# PIC32CM1216LS00048 register map
Vendor: Microchip Technology; Series: PIC32CMLS00; File version: 0
CPU: CM23 r0p0, little endian, MPU, no FPU, 2 interrupt priority bits, 71 interrupts
Registers are 32-bit, read-write, reset 0x0 unless marked. A register's access mark holds for its fields unless they carry their own. Offsets are from the block's base; [hi:lo] are bit positions; lines under a group give offsets from that group; {n}, {i} and the like mark numbered series; 'fields as' and 'values as' point back to an identical list.

## EIC — External Interrupt Controller
Base 0x40002800
Same registers: EIC_SEC 0x40002A00
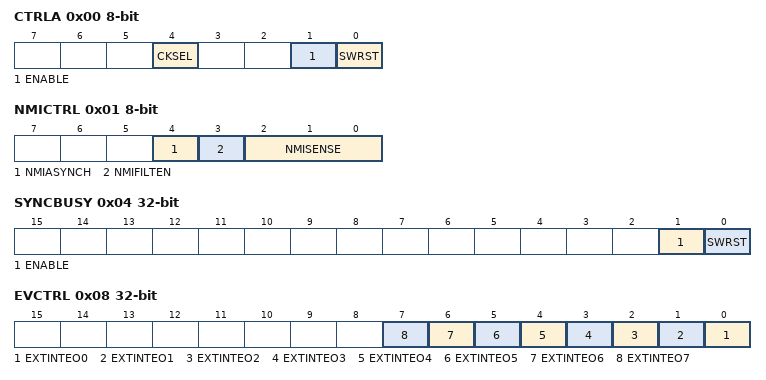
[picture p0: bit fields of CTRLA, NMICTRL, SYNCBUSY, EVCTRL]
0x00 CTRLA 8-bit — Control A
  [4] CKSEL — Clock Selection
    0=CLK_GCLK (Clocked by GCLK); 1=CLK_ULP32K (Clocked by ULP32K)
  [1] ENABLE
  [0] SWRST — Software Reset
0x01 NMICTRL 8-bit — Non-Maskable Interrupt Control
  [4] NMIASYNCH — Asynchronous Edge Detection Mode
    0=SYNC (Edge detection is clock synchronously operated); 1=ASYNC (Edge detection is clock asynchronously operated)
  [3] NMIFILTEN — Non-Maskable Interrupt Filter Enable
  [2:0] NMISENSE — Non-Maskable Interrupt Sense Configuration
    0=NONE (No detection); 1=RISE (Rising-edge detection); 2=FALL (Falling-edge detection); 3=BOTH (Both-edges detection); 4=HIGH (High-level detection); 5=LOW (Low-level detection)
0x02 NMIFLAG 8-bit write-1-clears — Non-Maskable Interrupt Flag Status and Clear
  [0] NMI — Non-Maskable Interrupt
0x04 SYNCBUSY ro — Synchronization Busy
  [1] ENABLE — Enable Synchronization Busy Status
  [0] SWRST — Software Reset Synchronization Busy Status
0x08 EVCTRL — Event Control
  [n] EXTINTEO{n} (n=0..7) — External Interrupt {n} Event Output Enable
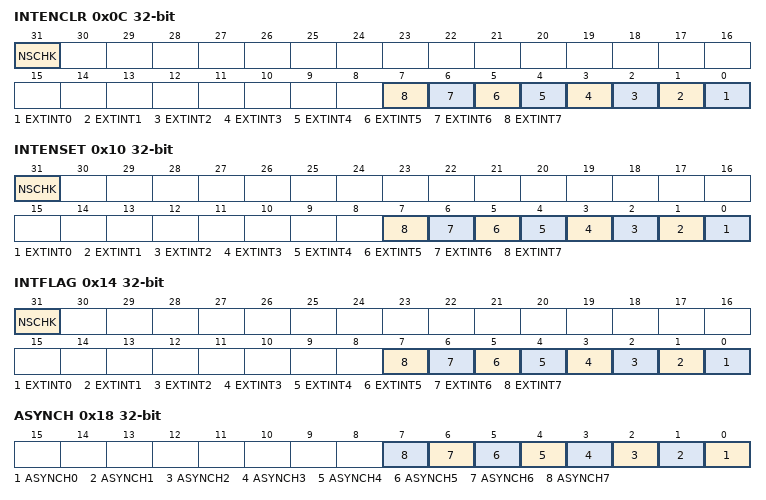
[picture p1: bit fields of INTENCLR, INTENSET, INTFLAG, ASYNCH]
0x0C INTENCLR write-1-clears — Interrupt Enable Clear
  [31] NSCHK — Non-secure Check Interrupt Enable
  [n] EXTINT{n} (n=0..7) — External Interrupt {n} Enable
0x10 INTENSET write-1-sets — Interrupt Enable Set
  fields as INTENCLR
0x14 INTFLAG write-1-clears — Interrupt Flag Status and Clear
  [31] NSCHK — Non-secure Check Interrupt
  [n] EXTINT{n} (n=0..7) — External Interrupt {n}
0x18 ASYNCH — External Interrupt Asynchronous Mode
  [all] fields
    values as NMICTRL.NMIASYNCH
  [n] ASYNCH{n} (n=0..7) — Asynchronous Edge Detection Mode of EXTINT{n}
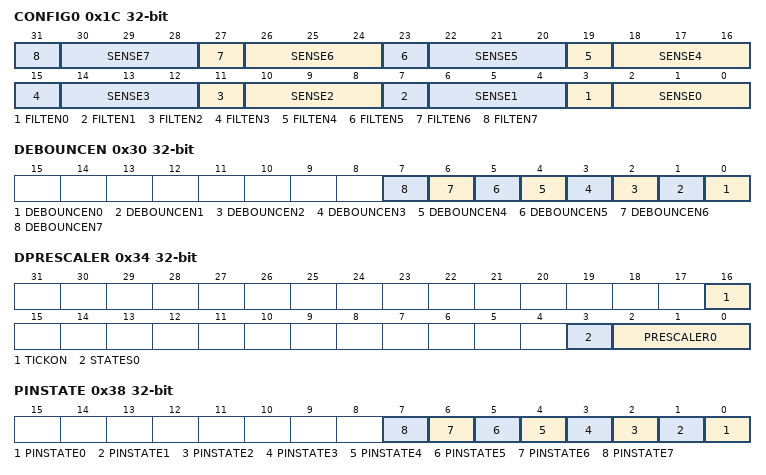
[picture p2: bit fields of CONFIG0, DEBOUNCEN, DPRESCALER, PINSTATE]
0x1C CONFIG0 — External Interrupt Sense Configuration
  [4n+3] FILTEN{n} (n=0..7) — Filter Enable {n}
  [4n+2:4n] SENSE{n} (n=0..7) — Input Sense Configuration {n}
    0=NONE (No detection); 1=RISE (Rising edge detection); 2=FALL (Falling edge detection); 3=BOTH (Both edges detection); 4=HIGH (High level detection); 5=LOW (Low level detection)
0x30 DEBOUNCEN — Debouncer Enable
  [n] DEBOUNCEN{n} (n=0..7) — Debouncer Enable of EXTINT{n}
0x34 DPRESCALER — Debouncer Prescaler
  [16] TICKON — Pin Sampler frequency selection
    0=CLK_GCLK_EIC (Clocked by GCLK); 1=CLK_LFREQ (Clocked by Low Frequency Clock)
  [3] STATES0 — Debouncer number of states
    0=LFREQ3 (3 low frequency samples); 1=LFREQ7 (7 low frequency samples)
  [2:0] PRESCALER0 — Debouncer Prescaler
    0=DIV2 (EIC clock divided by 2); 1=DIV4 (EIC clock divided by 4); 2=DIV8 (EIC clock divided by 8); 3=DIV16 (EIC clock divided by 16); 4=DIV32 (EIC clock divided by 32); 5=DIV64 (EIC clock divided by 64); 6=DIV128 (EIC clock divided by 128); 7=DIV256 (EIC clock divided by 256)
0x38 PINSTATE ro
  [n] PINSTATE{n} (n=0..7) — Pin State of EXTINT{n}
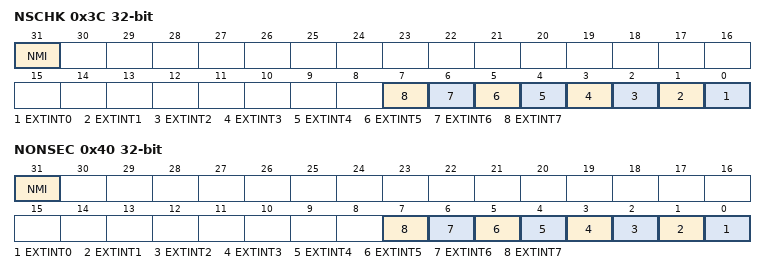
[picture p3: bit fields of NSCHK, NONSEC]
0x3C NSCHK — Non-secure Interrupt Check Enable
  [31] NMI — Non-Maskable External Interrupt Nonsecure Check Enable
  [n] EXTINT{n} (n=0..7) — External Interrupt {n} Nonsecure Check Enable
0x40 NONSEC — Non-secure Interrupt
  [31] NMI — Non-Maskable Interrupt Nonsecure Enable
  [n] EXTINT{n} (n=0..7) — External Interrupt {n} Nonsecure Enable

## EVSYS — Event System Interface
Base 0x42000000
Same registers: EVSYS_SEC 0x42000200
0x00 CTRLA 8-bit wo — Control
  [0] SWRST — Software Reset
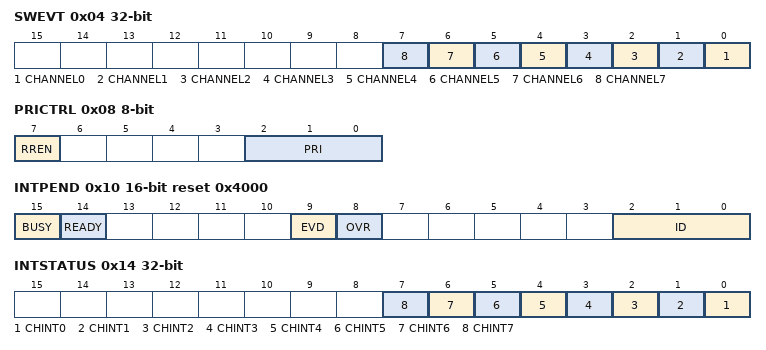
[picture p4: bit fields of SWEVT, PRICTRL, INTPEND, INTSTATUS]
0x04 SWEVT wo — Software Event
  [n] CHANNEL{n} (n=0..7) — Channel {n} Software Selection
0x08 PRICTRL 8-bit — Priority Control
  [7] RREN — Round-Robin Scheduling Enable
  [2:0] PRI — Channel Priority Number
0x10 INTPEND 16-bit reset 0x4000 — Channel Pending Interrupt
  [15] BUSY
  [14] READY
  [9] EVD — Channel Event Detected
  [8] OVR — Channel Overrun
  [2:0] ID — Channel ID
0x14 INTSTATUS ro — Interrupt Status
  [n] CHINT{n} (n=0..7) — Channel {n} Pending Interrupt
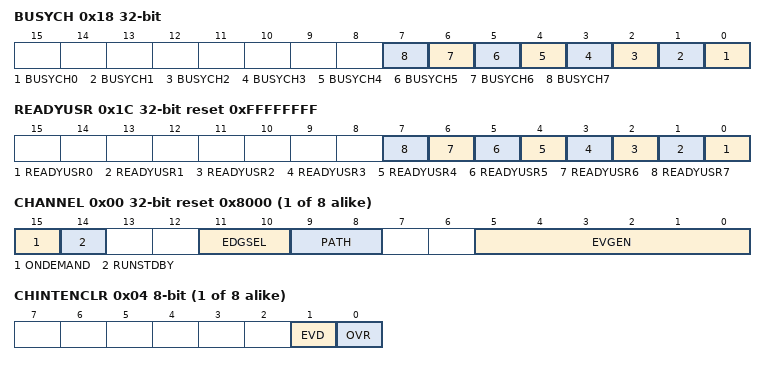
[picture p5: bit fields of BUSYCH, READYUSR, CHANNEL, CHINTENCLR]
0x18 BUSYCH ro — Busy Channels
  [n] BUSYCH{n} (n=0..7) — Busy Channel {n}
0x1C READYUSR ro reset 0xFFFFFFFF — Ready Users
  [n] READYUSR{n} (n=0..7) — Ready User for Channel {n}
{0x20+8i} CHANNEL[{i}] (i=0..7) group
  0x00 CHANNEL reset 0x8000 — Channel n Control
    [15] ONDEMAND — Generic Clock On Demand
    [14] RUNSTDBY — Run in standby
    [11:10] EDGSEL — Edge Detection Selection
      0=NO_EVT_OUTPUT (No event output when using the resynchronized or synchronous path); 1=RISING_EDGE (Event detection only on the rising edge of the signal from the event generator when using the resynchronized or synchronous path); 2=FALLING_EDGE (Event detection only on the falling edge of the signal from the event generator when using the resynchronized or synchronous path); 3=BOTH_EDGES (Event detection on rising and falling edges of the signal from the event generator when using the resynchronized or synchronous path)
    [9:8] PATH — Path Selection
      0=SYNCHRONOUS (Synchronous path); 1=RESYNCHRONIZED (Resynchronized path); 2=ASYNCHRONOUS (Asynchronous path)
    [5:0] EVGEN — Event Generator Selection
  0x04 CHINTENCLR 8-bit write-1-clears — Channel n Interrupt Enable Clear
    [1] EVD — Channel Event Detected Interrupt Disable
    [0] OVR — Channel Overrun Interrupt Disable
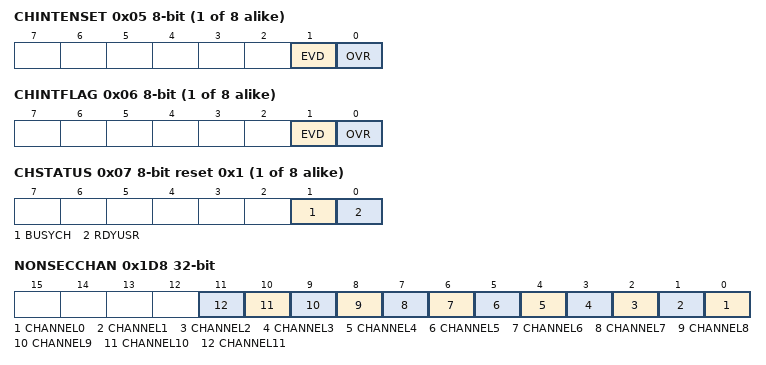
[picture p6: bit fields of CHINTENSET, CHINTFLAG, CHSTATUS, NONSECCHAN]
  0x05 CHINTENSET 8-bit write-1-sets — Channel n Interrupt Enable Set
    [1] EVD — Channel Event Detected Interrupt Enable
    [0] OVR — Channel Overrun Interrupt Enable
  0x06 CHINTFLAG 8-bit write-1-clears — Channel n Interrupt Flag Status and Clear
    [1] EVD — Channel Event Detected
    [0] OVR — Channel Overrun
  0x07 CHSTATUS 8-bit ro reset 0x1 — Channel n Status
    [1] BUSYCH — Busy Channel
    [0] RDYUSR — Ready User
{0x120+i} USER[{i}] (i=0..27) 8-bit — User Multiplexer n
  [3:0] CHANNEL — Channel Event Selection
0x1D4 INTENCLR 8-bit write-1-clears — Interrupt Enable Clear
  [0] NSCHK — Non-Secure Check Interrupt Enable
0x1D5 INTENSET 8-bit write-1-sets — Interrupt Enable Set
  [0] NSCHK — Non-Secure Check Interrupt Enable
0x1D6 INTFLAG 8-bit write-1-clears — Interrupt Flag Status and Clear
  [0] NSCHK — Non-Secure Check
0x1D8 NONSECCHAN — Channels Security Attribution
  [n] CHANNEL{n} (n=0..11) — Non-Secure for Channel {n}
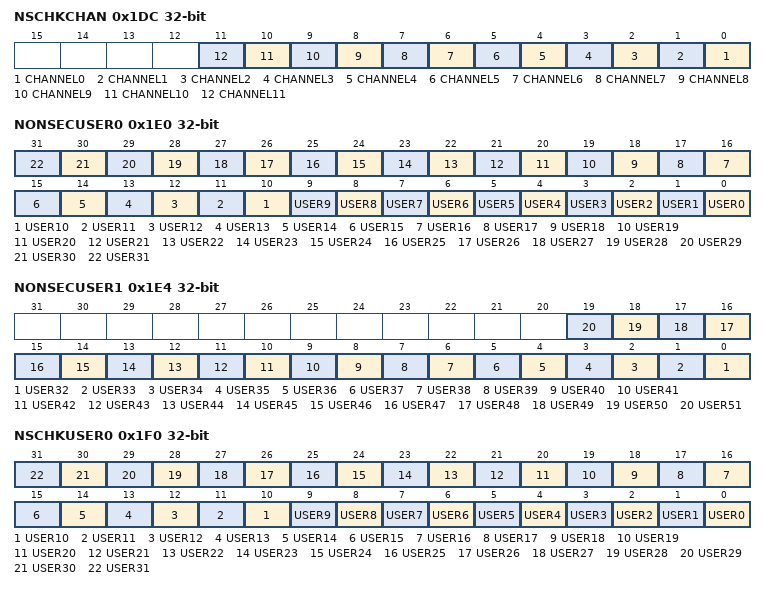
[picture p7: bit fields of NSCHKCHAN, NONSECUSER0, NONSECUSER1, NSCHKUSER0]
0x1DC NSCHKCHAN — Non-Secure Channels Check
  [n] CHANNEL{n} (n=0..11) — Channel {n} to be checked as non-secured
0x1E0 NONSECUSER0 — Users Security Attribution
  [n] USER{n} (n=0..31) — Non-Secure for User {n}
0x1E4 NONSECUSER1 — Users Security Attribution
  [n-32] USER{n} (n=32..51) — Non-Secure for User {n}
0x1F0 NSCHKUSER0 — Non-Secure Users Check
  [n] USER{n} (n=0..31) — User {n} to be checked as non-secured
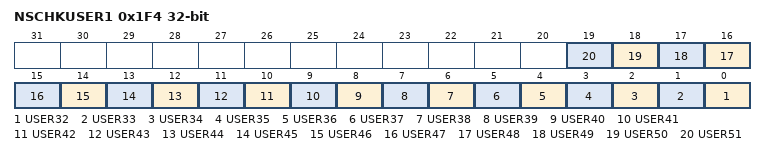
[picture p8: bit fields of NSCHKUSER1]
0x1F4 NSCHKUSER1 — Non-Secure Users Check
  [n-32] USER{n} (n=32..51) — User {n} to be checked as non-secured
